AUTOSAR XML (schema 4-2-2)
package /STELLANTIS/EPT/ASWCs
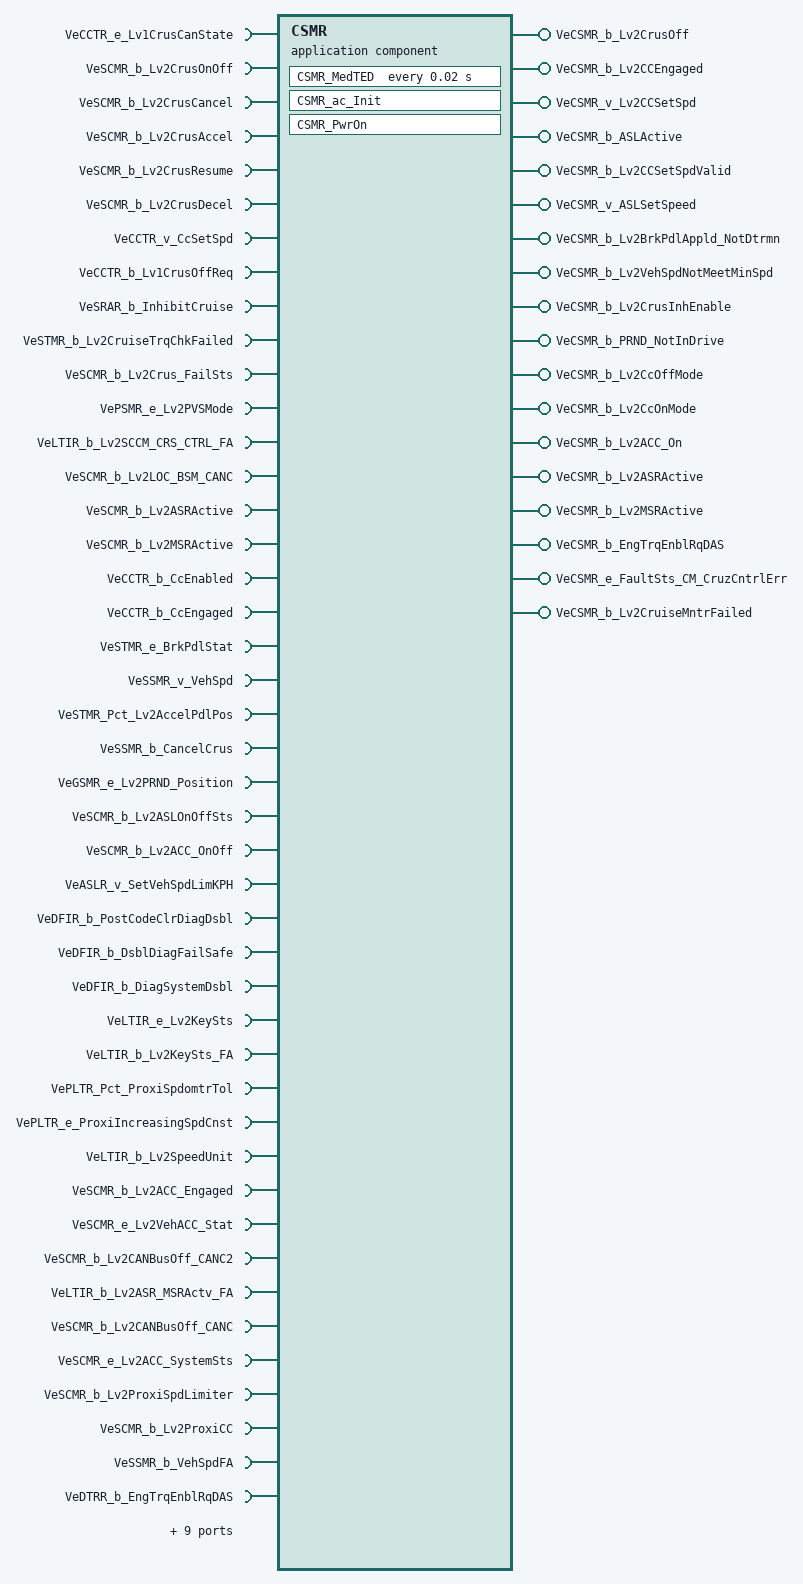
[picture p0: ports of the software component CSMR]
  application sw component type CSMR
    51 x require port:
      VeCCTR_e_Lv1CrusCanState: nonqueued-receiver-com-spec{data-element=Value, init-value=0}, required-interface=VeCCTR_e_Lv1CrusCanState
      VeSCMR_b_Lv2CrusOnOff: nonqueued-receiver-com-spec{data-element=Value, init-value=0}, required-interface=VeSCMR_b_Lv2CrusOnOff
      VeSCMR_b_Lv2CrusCancel: nonqueued-receiver-com-spec{data-element=Value, init-value=0}, required-interface=VeSCMR_b_Lv2CrusCancel
      VeSCMR_b_Lv2CrusAccel: nonqueued-receiver-com-spec{data-element=Value, init-value=0}, required-interface=VeSCMR_b_Lv2CrusAccel
      VeSCMR_b_Lv2CrusResume: nonqueued-receiver-com-spec{data-element=Value, init-value=0}, required-interface=VeSCMR_b_Lv2CrusResume
      VeSCMR_b_Lv2CrusDecel: nonqueued-receiver-com-spec{data-element=Value, init-value=0}, required-interface=VeSCMR_b_Lv2CrusDecel
      VeCCTR_v_CcSetSpd: nonqueued-receiver-com-spec{data-element=Value, init-value=0}, required-interface=VeCCTR_v_CcSetSpd
      VeCCTR_b_Lv1CrusOffReq: nonqueued-receiver-com-spec{data-element=Value, init-value=0}, required-interface=VeCCTR_b_Lv1CrusOffReq
      VeSRAR_b_InhibitCruise: nonqueued-receiver-com-spec{data-element=Value, init-value=0}, required-interface=VeSRAR_b_InhibitCruise
      VeSTMR_b_Lv2CruiseTrqChkFailed: nonqueued-receiver-com-spec{data-element=Value, init-value=0}, required-interface=VeSTMR_b_Lv2CruiseTrqChkFailed
      VeSCMR_b_Lv2Crus_FailSts: nonqueued-receiver-com-spec{data-element=Value, init-value=0}, required-interface=VeSCMR_b_Lv2Crus_FailSts
      VePSMR_e_Lv2PVSMode: nonqueued-receiver-com-spec{data-element=Value, init-value=CePSMR_e_NO_Fault}, required-interface=VePSMR_e_Lv2PVSMode
      VeLTIR_b_Lv2SCCM_CRS_CTRL_FA: nonqueued-receiver-com-spec{data-element=Value, init-value=0}, required-interface=VeLTIR_b_Lv2SCCM_CRS_CTRL_FA
      VeSCMR_b_Lv2LOC_BSM_CANC: nonqueued-receiver-com-spec{data-element=Value, init-value=0}, required-interface=VeSCMR_b_Lv2LOC_BSM_CANC
      VeSCMR_b_Lv2ASRActive: nonqueued-receiver-com-spec{data-element=Value, init-value=0}, required-interface=VeSCMR_b_Lv2ASRActive
      VeSCMR_b_Lv2MSRActive: nonqueued-receiver-com-spec{data-element=Value, init-value=0}, required-interface=VeSCMR_b_Lv2MSRActive
      VeCCTR_b_CcEnabled: nonqueued-receiver-com-spec{data-element=Value, init-value=0}, required-interface=VeCCTR_b_CcEnabled
      VeCCTR_b_CcEngaged: nonqueued-receiver-com-spec{data-element=Value, init-value=0}, required-interface=VeCCTR_b_CcEngaged
      VeSTMR_e_BrkPdlStat: nonqueued-receiver-com-spec{data-element=Value, init-value=CeSTMR_e_BrkStat_NotDtrmnd}, required-interface=VeSTMR_e_BrkPdlStat
      VeSSMR_v_VehSpd: nonqueued-receiver-com-spec{data-element=Value, init-value=0}, required-interface=VeSSMR_v_VehSpd
      VeSTMR_Pct_Lv2AccelPdlPos: nonqueued-receiver-com-spec{data-element=Value, init-value=0}, required-interface=VeSTMR_Pct_Lv2AccelPdlPos
      VeSSMR_b_CancelCrus: nonqueued-receiver-com-spec{data-element=Value, init-value=0}, required-interface=VeSSMR_b_CancelCrus
      VeGSMR_e_Lv2PRND_Position: nonqueued-receiver-com-spec{data-element=Value, init-value=CeGSMR_e_TransRangePark}, required-interface=VeGSMR_e_Lv2PRND_Position
      VeSCMR_b_Lv2ASLOnOffSts: nonqueued-receiver-com-spec{data-element=Value, init-value=0}, required-interface=VeSCMR_b_Lv2ASLOnOffSts
      VeSCMR_b_Lv2ACC_OnOff: nonqueued-receiver-com-spec{data-element=Value, init-value=0}, required-interface=VeSCMR_b_Lv2ACC_OnOff
      VeASLR_v_SetVehSpdLimKPH: nonqueued-receiver-com-spec{data-element=Value, init-value=0}, required-interface=VeASLR_v_SetVehSpdLimKPH
      VeDFIR_b_PostCodeClrDiagDsbl: nonqueued-receiver-com-spec{data-element=Value, init-value=0}, required-interface=VeDFIR_b_PostCodeClrDiagDsbl
      VeDFIR_b_DsblDiagFailSafe: nonqueued-receiver-com-spec{data-element=Value, init-value=0}, required-interface=VeDFIR_b_DsblDiagFailSafe
      VeDFIR_b_DiagSystemDsbl: nonqueued-receiver-com-spec{data-element=Value, init-value=0}, required-interface=VeDFIR_b_DiagSystemDsbl
      VeLTIR_e_Lv2KeySts: nonqueued-receiver-com-spec{data-element=Value, init-value=CeLTIR_e_IGN_LK}, required-interface=VeLTIR_e_Lv2KeySts
      VeLTIR_b_Lv2KeySts_FA: nonqueued-receiver-com-spec{data-element=Value, init-value=0}, required-interface=VeLTIR_b_Lv2KeySts_FA
      VePLTR_Pct_ProxiSpdomtrTol: nonqueued-receiver-com-spec{data-element=Value, init-value=0}, required-interface=VePLTR_Pct_ProxiSpdomtrTol
      VePLTR_e_ProxiIncreasingSpdCnst: nonqueued-receiver-com-spec{data-element=Value, init-value=CePLTR_e_Increasing_0}, required-interface=VePLTR_e_ProxiIncreasingSpdCnst
      VeLTIR_b_Lv2SpeedUnit: nonqueued-receiver-com-spec{data-element=Value, init-value=0}, required-interface=VeLTIR_b_Lv2SpeedUnit
      VeSCMR_b_Lv2ACC_Engaged: nonqueued-receiver-com-spec{data-element=Value, init-value=0}, required-interface=VeSCMR_b_Lv2ACC_Engaged
      VeSCMR_e_Lv2VehACC_Stat: nonqueued-receiver-com-spec{data-element=Value, init-value=CeCSMR_e_Lv2Absent}, required-interface=VeSCMR_e_Lv2VehACC_Stat
      VeSCMR_b_Lv2CANBusOff_CANC2: nonqueued-receiver-com-spec{data-element=Value, init-value=0}, required-interface=VeSCMR_b_Lv2CANBusOff_CANC2
      VeLTIR_b_Lv2ASR_MSRActv_FA: nonqueued-receiver-com-spec{data-element=Value, init-value=0}, required-interface=VeLTIR_b_Lv2ASR_MSRActv_FA
      VeSCMR_b_Lv2CANBusOff_CANC: nonqueued-receiver-com-spec{data-element=Value, init-value=0}, required-interface=VeSCMR_b_Lv2CANBusOff_CANC
      VeSCMR_e_Lv2ACC_SystemSts: nonqueued-receiver-com-spec{data-element=Value, init-value=CeSTMR_e_Off_M182}, required-interface=VeSCMR_e_Lv2ACC_SystemSts
      VeSCMR_b_Lv2ProxiSpdLimiter: nonqueued-receiver-com-spec{data-element=Value, init-value=0}, required-interface=VeSCMR_b_Lv2ProxiSpdLimiter
      VeSCMR_b_Lv2ProxiCC: nonqueued-receiver-com-spec{data-element=Value, init-value=0}, required-interface=VeSCMR_b_Lv2ProxiCC
      VeSSMR_b_VehSpdFA: nonqueued-receiver-com-spec{data-element=Value, init-value=0}, required-interface=VeSSMR_b_VehSpdFA
      VeDTRR_b_EngTrqEnblRqDAS: nonqueued-receiver-com-spec{data-element=Value, init-value=0}, required-interface=VeDTRR_b_EngTrqEnblRqDAS
      VeASLR_b_ASLEnabled: nonqueued-receiver-com-spec{data-element=Value, init-value=0}, required-interface=VeASLR_b_ASLEnabled
      VeSTMR_M_Lv2PtcWhlCcTrqReq: nonqueued-receiver-com-spec{data-element=Value, init-value=0}, required-interface=VeSTMR_M_Lv2PtcWhlCcTrqReq
      VeSTMR_M_Lv2AccelPdlWhlTrq: nonqueued-receiver-com-spec{data-element=Value, init-value=0}, required-interface=VeSTMR_M_Lv2AccelPdlWhlTrq
      VeCCTR_b_CcInhEngage: nonqueued-receiver-com-spec{data-element=Value, init-value=0}, required-interface=VeCCTR_b_CcInhEngage
      VeLTIR_b_Lv2SpeedUnit_FA: nonqueued-receiver-com-spec{data-element=Value, init-value=0}, required-interface=VeLTIR_b_Lv2SpeedUnit_FA
      VeSCMR_b_Lv2LOC_BCM_CANC: nonqueued-receiver-com-spec{data-element=Value, init-value=0}, required-interface=VeSCMR_b_Lv2LOC_BCM_CANC
      VeDMAB_y_StatusByte_CM_CruzCntrlErr: nonqueued-receiver-com-spec{data-element=Value, init-value=0}, required-interface=VeDMAB_y_StatusByte_CM_CruzCntrlErr
    18 x provide port:
      VeCSMR_b_Lv2CrusOff: nonqueued-sender-com-spec{data-element=Value, init-value=0}, provided-interface=VeCSMR_b_Lv2CrusOff
      VeCSMR_b_Lv2CCEngaged: nonqueued-sender-com-spec{data-element=Value, init-value=0}, provided-interface=VeCSMR_b_Lv2CCEngaged
      VeCSMR_v_Lv2CCSetSpd: nonqueued-sender-com-spec{data-element=Value, init-value=0}, provided-interface=VeCSMR_v_Lv2CCSetSpd
      VeCSMR_b_ASLActive: nonqueued-sender-com-spec{data-element=Value, init-value=0}, provided-interface=VeCSMR_b_ASLActive
      VeCSMR_b_Lv2CCSetSpdValid: nonqueued-sender-com-spec{data-element=Value, init-value=0}, provided-interface=VeCSMR_b_Lv2CCSetSpdValid
      VeCSMR_v_ASLSetSpeed: nonqueued-sender-com-spec{data-element=Value, init-value=0}, provided-interface=VeCSMR_v_ASLSetSpeed
      VeCSMR_b_Lv2BrkPdlAppld_NotDtrmn: nonqueued-sender-com-spec{data-element=Value, init-value=0}, provided-interface=VeCSMR_b_Lv2BrkPdlAppld_NotDtrmn
      VeCSMR_b_Lv2VehSpdNotMeetMinSpd: nonqueued-sender-com-spec{data-element=Value, init-value=0}, provided-interface=VeCSMR_b_Lv2VehSpdNotMeetMinSpd
      VeCSMR_b_Lv2CrusInhEnable: nonqueued-sender-com-spec{data-element=Value, init-value=0}, provided-interface=VeCSMR_b_Lv2CrusInhEnable
      VeCSMR_b_PRND_NotInDrive: nonqueued-sender-com-spec{data-element=Value, init-value=0}, provided-interface=VeCSMR_b_PRND_NotInDrive
      VeCSMR_b_Lv2CcOffMode: nonqueued-sender-com-spec{data-element=Value, init-value=0}, provided-interface=VeCSMR_b_Lv2CcOffMode
      VeCSMR_b_Lv2CcOnMode: nonqueued-sender-com-spec{data-element=Value, init-value=0}, provided-interface=VeCSMR_b_Lv2CcOnMode
      VeCSMR_b_Lv2ACC_On: nonqueued-sender-com-spec{data-element=Value, init-value=0}, provided-interface=VeCSMR_b_Lv2ACC_On
      VeCSMR_b_Lv2ASRActive: nonqueued-sender-com-spec{data-element=Value, init-value=0}, provided-interface=VeCSMR_b_Lv2ASRActive
      VeCSMR_b_Lv2MSRActive: nonqueued-sender-com-spec{data-element=Value, init-value=0}, provided-interface=VeCSMR_b_Lv2MSRActive
      VeCSMR_b_EngTrqEnblRqDAS: nonqueued-sender-com-spec{data-element=Value, init-value=0}, provided-interface=VeCSMR_b_EngTrqEnblRqDAS
      VeCSMR_e_FaultSts_CM_CruzCntrlErr: nonqueued-sender-com-spec{data-element=Value, init-value=CeDFIB_e_Init}, provided-interface=VeCSMR_e_FaultSts_CM_CruzCntrlErr
      VeCSMR_b_Lv2CruiseMntrFailed: nonqueued-sender-com-spec{data-element=Value, init-value=0}, provided-interface=VeCSMR_b_Lv2CruiseMntrFailed
    require port CSMR_FastTEF_StartCheckpoint: client-com-spec=CheckpointReached, required-interface=WdgM_LocalSupervision
    require port CSMR_FastTEF_StopCheckpoint: client-com-spec=CheckpointReached, required-interface=WdgM_LocalSupervision
    behavior IB_CSMR: data-type-mapping=msADTtoIDTMapping, handle-termination-and-restart=NO-SUPPORT, included-data-type-set=data-type=[TeCSMR_e_CC_State, TeCSMR_e_CC_State_SF]
      timing event Event_MedTED: start-on-event=CSMR_MedTED, period=0.02
      init event Event_CSMR_ac_Init: start-on-event=CSMR_ac_Init
      init event Event_PwrOn: start-on-event=CSMR_PwrOn
      runnable CSMR_ac_Init
        data-send-points:
          access OUT_VeCSMR_e_FaultSts_CM_CruzCntrlErr_Value: accessed-variable=VeCSMR_e_FaultSts_CM_CruzCntrlErr.Value
      runnable CSMR_MedTED
        data-receive-point-by-arguments:
          51 x access:
            IN_VeASLR_b_ASLEnabled_Value: accessed-variable=VeASLR_b_ASLEnabled.Value
            IN_VeASLR_v_SetVehSpdLimKPH_Value: accessed-variable=VeASLR_v_SetVehSpdLimKPH.Value
            IN_VeCCTR_b_CcEnabled_Value: accessed-variable=VeCCTR_b_CcEnabled.Value
            IN_VeCCTR_b_CcEngaged_Value: accessed-variable=VeCCTR_b_CcEngaged.Value
            IN_VeCCTR_b_CcInhEngage_Value: accessed-variable=VeCCTR_b_CcInhEngage.Value
            IN_VeCCTR_b_Lv1CrusOffReq_Value: accessed-variable=VeCCTR_b_Lv1CrusOffReq.Value
            IN_VeCCTR_e_Lv1CrusCanState_Value: accessed-variable=VeCCTR_e_Lv1CrusCanState.Value
            IN_VeCCTR_v_CcSetSpd_Value: accessed-variable=VeCCTR_v_CcSetSpd.Value
            IN_VeDFIR_b_DiagSystemDsbl_Value: accessed-variable=VeDFIR_b_DiagSystemDsbl.Value
            IN_VeDFIR_b_DsblDiagFailSafe_Value: accessed-variable=VeDFIR_b_DsblDiagFailSafe.Value
            IN_VeDFIR_b_PostCodeClrDiagDsbl_Value: accessed-variable=VeDFIR_b_PostCodeClrDiagDsbl.Value
            IN_VeDMAB_y_StatusByte_CM_CruzCntrlErr_Value: accessed-variable=VeDMAB_y_StatusByte_CM_CruzCntrlErr.Value
            IN_VeDTRR_b_EngTrqEnblRqDAS_Value: accessed-variable=VeDTRR_b_EngTrqEnblRqDAS.Value
            IN_VeGSMR_e_Lv2PRND_Position_Value: accessed-variable=VeGSMR_e_Lv2PRND_Position.Value
            IN_VeLTIR_b_Lv2ASR_MSRActv_FA_Value: accessed-variable=VeLTIR_b_Lv2ASR_MSRActv_FA.Value
            IN_VeLTIR_b_Lv2KeySts_FA_Value: accessed-variable=VeLTIR_b_Lv2KeySts_FA.Value
            IN_VeLTIR_b_Lv2SCCM_CRS_CTRL_FA_Value: accessed-variable=VeLTIR_b_Lv2SCCM_CRS_CTRL_FA.Value
            IN_VeLTIR_b_Lv2SpeedUnit_Value: accessed-variable=VeLTIR_b_Lv2SpeedUnit.Value
            IN_VeLTIR_b_Lv2SpeedUnit_FA_Value: accessed-variable=VeLTIR_b_Lv2SpeedUnit_FA.Value
            IN_VeLTIR_e_Lv2KeySts_Value: accessed-variable=VeLTIR_e_Lv2KeySts.Value
            IN_VePLTR_Pct_ProxiSpdomtrTol_Value: accessed-variable=VePLTR_Pct_ProxiSpdomtrTol.Value
            IN_VePLTR_e_ProxiIncreasingSpdCnst_Value: accessed-variable=VePLTR_e_ProxiIncreasingSpdCnst.Value
            IN_VePSMR_e_Lv2PVSMode_Value: accessed-variable=VePSMR_e_Lv2PVSMode.Value
            IN_VeSCMR_b_Lv2ACC_Engaged_Value: accessed-variable=VeSCMR_b_Lv2ACC_Engaged.Value
            IN_VeSCMR_b_Lv2ACC_OnOff_Value: accessed-variable=VeSCMR_b_Lv2ACC_OnOff.Value
            IN_VeSCMR_b_Lv2ASLOnOffSts_Value: accessed-variable=VeSCMR_b_Lv2ASLOnOffSts.Value
            IN_VeSCMR_b_Lv2ASRActive_Value: accessed-variable=VeSCMR_b_Lv2ASRActive.Value
            IN_VeSCMR_b_Lv2CANBusOff_CANC_Value: accessed-variable=VeSCMR_b_Lv2CANBusOff_CANC.Value
            IN_VeSCMR_b_Lv2CANBusOff_CANC2_Value: accessed-variable=VeSCMR_b_Lv2CANBusOff_CANC2.Value
            IN_VeSCMR_b_Lv2CrusAccel_Value: accessed-variable=VeSCMR_b_Lv2CrusAccel.Value
            IN_VeSCMR_b_Lv2CrusCancel_Value: accessed-variable=VeSCMR_b_Lv2CrusCancel.Value
            IN_VeSCMR_b_Lv2CrusDecel_Value: accessed-variable=VeSCMR_b_Lv2CrusDecel.Value
            IN_VeSCMR_b_Lv2CrusOnOff_Value: accessed-variable=VeSCMR_b_Lv2CrusOnOff.Value
            IN_VeSCMR_b_Lv2CrusResume_Value: accessed-variable=VeSCMR_b_Lv2CrusResume.Value
            IN_VeSCMR_b_Lv2Crus_FailSts_Value: accessed-variable=VeSCMR_b_Lv2Crus_FailSts.Value
            IN_VeSCMR_b_Lv2LOC_BCM_CANC_Value: accessed-variable=VeSCMR_b_Lv2LOC_BCM_CANC.Value
            IN_VeSCMR_b_Lv2LOC_BSM_CANC_Value: accessed-variable=VeSCMR_b_Lv2LOC_BSM_CANC.Value
            IN_VeSCMR_b_Lv2MSRActive_Value: accessed-variable=VeSCMR_b_Lv2MSRActive.Value
            IN_VeSCMR_b_Lv2ProxiCC_Value: accessed-variable=VeSCMR_b_Lv2ProxiCC.Value
            IN_VeSCMR_b_Lv2ProxiSpdLimiter_Value: accessed-variable=VeSCMR_b_Lv2ProxiSpdLimiter.Value
            IN_VeSCMR_e_Lv2ACC_SystemSts_Value: accessed-variable=VeSCMR_e_Lv2ACC_SystemSts.Value
            IN_VeSCMR_e_Lv2VehACC_Stat_Value: accessed-variable=VeSCMR_e_Lv2VehACC_Stat.Value
            IN_VeSRAR_b_InhibitCruise_Value: accessed-variable=VeSRAR_b_InhibitCruise.Value
            IN_VeSSMR_b_CancelCrus_Value: accessed-variable=VeSSMR_b_CancelCrus.Value
            IN_VeSSMR_b_VehSpdFA_Value: accessed-variable=VeSSMR_b_VehSpdFA.Value
            IN_VeSSMR_v_VehSpd_Value: accessed-variable=VeSSMR_v_VehSpd.Value
            IN_VeSTMR_M_Lv2AccelPdlWhlTrq_Value: accessed-variable=VeSTMR_M_Lv2AccelPdlWhlTrq.Value
            IN_VeSTMR_M_Lv2PtcWhlCcTrqReq_Value: accessed-variable=VeSTMR_M_Lv2PtcWhlCcTrqReq.Value
            IN_VeSTMR_Pct_Lv2AccelPdlPos_Value: accessed-variable=VeSTMR_Pct_Lv2AccelPdlPos.Value
            IN_VeSTMR_b_Lv2CruiseTrqChkFailed_Value: accessed-variable=VeSTMR_b_Lv2CruiseTrqChkFailed.Value
            IN_VeSTMR_e_BrkPdlStat_Value: accessed-variable=VeSTMR_e_BrkPdlStat.Value
        data-send-points:
          18 x access:
            OUT_VeCSMR_b_Lv2CrusOff_Value: accessed-variable=VeCSMR_b_Lv2CrusOff.Value
            OUT_VeCSMR_b_Lv2CCEngaged_Value: accessed-variable=VeCSMR_b_Lv2CCEngaged.Value
            OUT_VeCSMR_v_Lv2CCSetSpd_Value: accessed-variable=VeCSMR_v_Lv2CCSetSpd.Value
            OUT_VeCSMR_b_ASLActive_Value: accessed-variable=VeCSMR_b_ASLActive.Value
            OUT_VeCSMR_b_Lv2CCSetSpdValid_Value: accessed-variable=VeCSMR_b_Lv2CCSetSpdValid.Value
            OUT_VeCSMR_v_ASLSetSpeed_Value: accessed-variable=VeCSMR_v_ASLSetSpeed.Value
            OUT_VeCSMR_b_Lv2BrkPdlAppld_NotDtrmn_Value: accessed-variable=VeCSMR_b_Lv2BrkPdlAppld_NotDtrmn.Value
            OUT_VeCSMR_b_Lv2VehSpdNotMeetMinSpd_Value: accessed-variable=VeCSMR_b_Lv2VehSpdNotMeetMinSpd.Value
            OUT_VeCSMR_b_Lv2CrusInhEnable_Value: accessed-variable=VeCSMR_b_Lv2CrusInhEnable.Value
            OUT_VeCSMR_b_PRND_NotInDrive_Value: accessed-variable=VeCSMR_b_PRND_NotInDrive.Value
            OUT_VeCSMR_b_Lv2CcOffMode_Value: accessed-variable=VeCSMR_b_Lv2CcOffMode.Value
            OUT_VeCSMR_b_Lv2CcOnMode_Value: accessed-variable=VeCSMR_b_Lv2CcOnMode.Value
            OUT_VeCSMR_b_Lv2ACC_On_Value: accessed-variable=VeCSMR_b_Lv2ACC_On.Value
            OUT_VeCSMR_b_Lv2ASRActive_Value: accessed-variable=VeCSMR_b_Lv2ASRActive.Value
            OUT_VeCSMR_b_Lv2MSRActive_Value: accessed-variable=VeCSMR_b_Lv2MSRActive.Value
            OUT_VeCSMR_b_EngTrqEnblRqDAS_Value: accessed-variable=VeCSMR_b_EngTrqEnblRqDAS.Value
            OUT_VeCSMR_e_FaultSts_CM_CruzCntrlErr_Value: accessed-variable=VeCSMR_e_FaultSts_CM_CruzCntrlErr.Value
            OUT_VeCSMR_b_Lv2CruiseMntrFailed_Value: accessed-variable=VeCSMR_b_Lv2CruiseMntrFailed.Value
        sync call SC_CSMR_FastTEF_StartCheckpoint_CheckpointReached: operation=CSMR_FastTEF_StartCheckpoint.CheckpointReached, timeout=1E-06
        sync call SC_CSMR_FastTEF_StopCheckpoint_CheckpointReached: operation=CSMR_FastTEF_StopCheckpoint.CheckpointReached, timeout=1E-06
      runnable CSMR_PwrOn
        data-send-points:
          18 x access:
            OUT_VeCSMR_b_Lv2CrusOff_Value: accessed-variable=VeCSMR_b_Lv2CrusOff.Value
            OUT_VeCSMR_b_Lv2CCEngaged_Value: accessed-variable=VeCSMR_b_Lv2CCEngaged.Value
            OUT_VeCSMR_v_Lv2CCSetSpd_Value: accessed-variable=VeCSMR_v_Lv2CCSetSpd.Value
            OUT_VeCSMR_b_ASLActive_Value: accessed-variable=VeCSMR_b_ASLActive.Value
            OUT_VeCSMR_b_Lv2CCSetSpdValid_Value: accessed-variable=VeCSMR_b_Lv2CCSetSpdValid.Value
            OUT_VeCSMR_v_ASLSetSpeed_Value: accessed-variable=VeCSMR_v_ASLSetSpeed.Value
            OUT_VeCSMR_b_Lv2BrkPdlAppld_NotDtrmn_Value: accessed-variable=VeCSMR_b_Lv2BrkPdlAppld_NotDtrmn.Value
            OUT_VeCSMR_b_Lv2VehSpdNotMeetMinSpd_Value: accessed-variable=VeCSMR_b_Lv2VehSpdNotMeetMinSpd.Value
            OUT_VeCSMR_b_Lv2CrusInhEnable_Value: accessed-variable=VeCSMR_b_Lv2CrusInhEnable.Value
            OUT_VeCSMR_b_PRND_NotInDrive_Value: accessed-variable=VeCSMR_b_PRND_NotInDrive.Value
            OUT_VeCSMR_b_Lv2CcOffMode_Value: accessed-variable=VeCSMR_b_Lv2CcOffMode.Value
            OUT_VeCSMR_b_Lv2CcOnMode_Value: accessed-variable=VeCSMR_b_Lv2CcOnMode.Value
            OUT_VeCSMR_b_Lv2ACC_On_Value: accessed-variable=VeCSMR_b_Lv2ACC_On.Value
            OUT_VeCSMR_b_Lv2ASRActive_Value: accessed-variable=VeCSMR_b_Lv2ASRActive.Value
            OUT_VeCSMR_b_Lv2MSRActive_Value: accessed-variable=VeCSMR_b_Lv2MSRActive.Value
            OUT_VeCSMR_b_EngTrqEnblRqDAS_Value: accessed-variable=VeCSMR_b_EngTrqEnblRqDAS.Value
            OUT_VeCSMR_e_FaultSts_CM_CruzCntrlErr_Value: accessed-variable=VeCSMR_e_FaultSts_CM_CruzCntrlErr.Value
            OUT_VeCSMR_b_Lv2CruiseMntrFailed_Value: accessed-variable=VeCSMR_b_Lv2CruiseMntrFailed.Value
